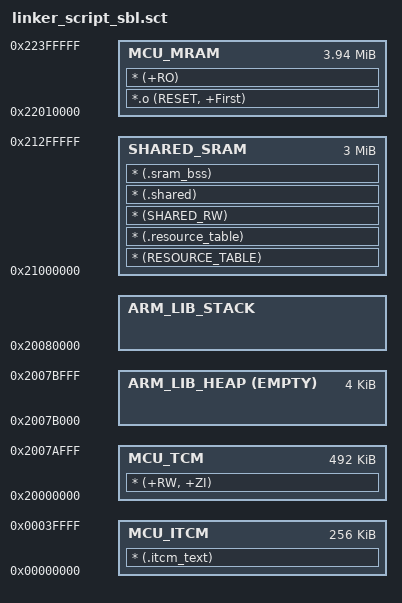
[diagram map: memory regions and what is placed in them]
;******************************************************************************
;
; Scatter file for Keil linker configuration.
;
;******************************************************************************
; atomiq110 FPGA: MRAM is emulated at 0x22000000 and SRAM at 0x21000000, unlike
; Apollo5 silicon (0x00400000 / 0x20080000). This "sbl" variant reserves the first
; 64 KB of MRAM for the secure bootloader -> app base 0x22010000. Use the nbl scatter
; (LR_1 0x22000000) when there is no bootloader.
LR_1 0x22010000
{
    MCU_MRAM 0x22010000 0x003F0000
    {
        *.o (RESET, +First)
        * (+RO)
    }

    MCU_ITCM 0x00000000 0x00040000
    {
        * (.itcm_text)
    }

    MCU_TCM 0x20000000 0x0007B000
    {
        * (+RW, +ZI)
    }

    ARM_LIB_HEAP  0x2007B000 EMPTY  0x00001000
    {   ; Reserve empty region for heap
    }

    SHARED_SRAM 0x21000000 0x00300000 ; 3 MB powered SSRAM (3x1MB blocks, PWRENSSRAM=7); upper 1 MB of the 4 MB aperture is unpopulated
    {
        * (RESOURCE_TABLE)
        * (.resource_table)
        * (SHARED_RW)
        * (.shared)
        * (.sram_bss)
    }

    ARM_LIB_STACK 0x20080000 EMPTY - 0x00004000
    {   ; Reserve empty region for stack
    }
}
